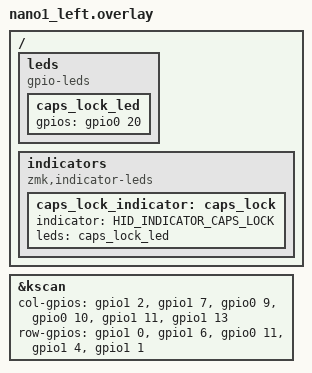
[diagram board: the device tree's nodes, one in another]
// This file was generated from a template. Edit it to match your keyboard.
// See https://zmk.dev/docs/development/hardware-integration/new-shield for more
// instructions.

#include "nano1.dtsi"
#pragma once

#include <dt-bindings/zmk/hid_usage.h>

// hid.h defines HID_USAGE_LED_NUM_LOCK as the minimum value, so that is bit
// zero in the report, and all other indicators are relative to that.

#define HID_INDICATOR_NUM_LOCK (1 << (HID_USAGE_LED_NUM_LOCK - HID_USAGE_LED_NUM_LOCK))
#define HID_INDICATOR_CAPS_LOCK (1 << (HID_USAGE_LED_CAPS_LOCK - HID_USAGE_LED_NUM_LOCK))
#define HID_INDICATOR_SCROLL_LOCK (1 << (HID_USAGE_LED_SCROLL_LOCK - HID_USAGE_LED_NUM_LOCK))
#define HID_INDICATOR_COMPOSE (1 << (HID_USAGE_LED_COMPOSE - HID_USAGE_LED_NUM_LOCK))
#define HID_INDICATOR_KANA (1 << (HID_USAGE_LED_KANA - HID_USAGE_LED_NUM_LOCK))
/ {
    leds {
        compatible = "gpio-leds";
        caps_lock_led: caps_lock_led {
            gpios = <&gpio0 20 GPIO_ACTIVE_HIGH>;
        };
    };
    indicators {
        compatible = "zmk,indicator-leds";

        caps_lock_indicator: caps_lock {
            indicator = <HID_INDICATOR_CAPS_LOCK>;
            leds = <&caps_lock_led>;
        };
    };
};
&kscan {
    // Replace these comments with the GPIO pins in the matrix for the left side.
    // See https://zmk.dev/docs/development/hardware-integration/new-shield#shield-overlays
    col-gpios
        = <&gpio1 2 (GPIO_ACTIVE_HIGH | GPIO_PULL_DOWN)>
        , <&gpio1 7 (GPIO_ACTIVE_HIGH | GPIO_PULL_DOWN)>
        , <&gpio0 9 (GPIO_ACTIVE_HIGH | GPIO_PULL_DOWN)>
        , <&gpio0 10 (GPIO_ACTIVE_HIGH | GPIO_PULL_DOWN)>
        , <&gpio1 11 (GPIO_ACTIVE_HIGH | GPIO_PULL_DOWN)>
        , <&gpio1 13 (GPIO_ACTIVE_HIGH | GPIO_PULL_DOWN)>
        ;
    row-gpios
        = <&gpio1 0 GPIO_ACTIVE_HIGH>
        , <&gpio1 6 GPIO_ACTIVE_HIGH>
        , <&gpio0 11 GPIO_ACTIVE_HIGH>
        , <&gpio1 4 GPIO_ACTIVE_HIGH>
        , <&gpio1 1 GPIO_ACTIVE_HIGH>
        ;
};
